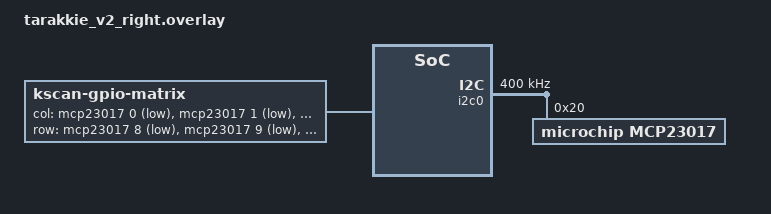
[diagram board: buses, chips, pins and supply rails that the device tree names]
#include <dt-bindings/zmk/matrix_transform.h>
#include <dt-bindings/zmk/keys.h>
#include <dt-bindings/zmk/mouse.h>
#include <dt-bindings/zmk/input.h>
#include <dt-bindings/gpio/gpio.h>
#include "tarakkie_v2.dtsi"
#include "module_1.dtsi"

/ {
    chosen {
        zmk,kscan = &kscan0;
        zmk,matrix_transform = &default_transform;
    };

    kscan0: kscan_0 {
        compatible = "zmk,kscan-gpio-matrix";
        label = "KSCAN";
        diode-direction = "col2row";

        col-gpios
            = <&mcp23017 0 GPIO_ACTIVE_LOW>
            , <&mcp23017 1 GPIO_ACTIVE_LOW>
            , <&mcp23017 2 GPIO_ACTIVE_LOW>
            , <&mcp23017 3 GPIO_ACTIVE_LOW>
            , <&mcp23017 4 GPIO_ACTIVE_LOW>
            ;

        row-gpios
            = <&mcp23017 8 (GPIO_ACTIVE_LOW | GPIO_PULL_UP)>
            , <&mcp23017 9 (GPIO_ACTIVE_LOW | GPIO_PULL_UP)>
            , <&mcp23017 10 (GPIO_ACTIVE_LOW | GPIO_PULL_UP)>
            , <&mcp23017 11 (GPIO_ACTIVE_LOW | GPIO_PULL_UP)>
            , <&mcp23017 12 (GPIO_ACTIVE_LOW | GPIO_PULL_UP)>
            , <&mcp23017 13 (GPIO_ACTIVE_LOW | GPIO_PULL_UP)>
            ;
    };
};

&i2c0 {
    status = "okay";
    // Removed pinctrl to avoid "undefined label" errors on xiao_ble
    clock-frequency = <I2C_BITRATE_FAST>;

    mcp23017: mcp23017@20 {
        compatible = "microchip,mcp23017";
        status = "okay";
        reg = <0x20>;
        gpio-controller;
        #gpio-cells = <2>;
    };
};
